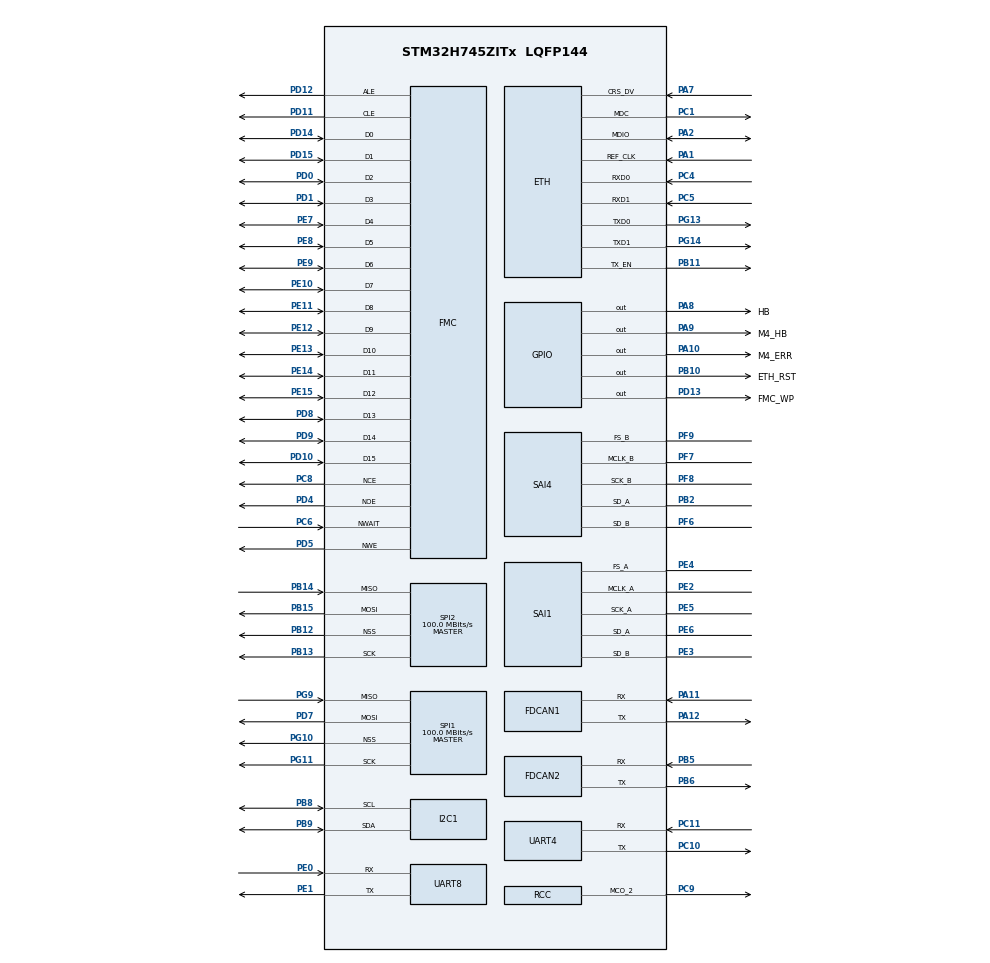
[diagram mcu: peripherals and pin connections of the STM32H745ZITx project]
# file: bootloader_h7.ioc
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CORTEX_M7.AccessPermission_S-Cortex_Memory_Protection_Unit_Region1_Settings_S=MPU_REGION_FULL_ACCESS
CORTEX_M7.AccessPermission_Spec=MPU_REGION_FULL_ACCESS
CORTEX_M7.BaseAddress_S-Cortex_Memory_Protection_Unit_Region1_Settings_S=0x30040000
CORTEX_M7.BaseAddress_Spec=0x30040000
CORTEX_M7.CPU_DCache=Enabled
CORTEX_M7.CPU_ICache=Enabled
CORTEX_M7.DisableExec_S-Cortex_Memory_Protection_Unit_Region1_Settings_S=MPU_INSTRUCTION_ACCESS_DISABLE
CORTEX_M7.Enable_S-Cortex_Memory_Protection_Unit_Region1_Settings_S=MPU_REGION_ENABLE
CORTEX_M7.IsBufferable_S-Cortex_Memory_Protection_Unit_Region1_Settings_S=MPU_ACCESS_BUFFERABLE
CORTEX_M7.IsShareable_S-Cortex_Memory_Protection_Unit_Region1_Settings_S=MPU_ACCESS_SHAREABLE
CORTEX_M7.IsShareable_Spec=MPU_ACCESS_NOT_SHAREABLE
CORTEX_M7.MPU_Control=__NULL
CORTEX_M7.Size_S-Cortex_Memory_Protection_Unit_Region1_Settings_S=MPU_REGION_SIZE_256B
CORTEX_M7.Size_Spec=MPU_REGION_SIZE_128KB
CORTEX_M7.SubRegionDisable_Spec=0x0
CORTEX_M7.TypeExtField_Spec=MPU_TEX_LEVEL1
CORTEX_M7.default_mode_Activation=1
CortexM4.IPs=CORTEX_M4\:I,DEBUG,FATFS_M4\:I,FREERTOS_M4\:I,IWDG2\:I,OPENAMP_M4\:I,PDM2PCM_M4\:I,PWR,RCC,RESMGR_UTILITY,SYS_M4\:I,USB_DEVICE_M4\:I,USB_HOST_M4\:I,VREFBUF,WWDG2\:I,DMA,BDMA,MDMA,NVIC2\:I,GPIO
CortexM4.Pins=PA9,PA10
CortexM7.IPs=CORTEX_M7\:I,DEBUG\:I,FATFS_M7\:I,FREERTOS_M7\:I,IWDG1\:I,OPENAMP_M7\:I,PDM2PCM_M7\:I,PWR\:I,RCC\:I,RESMGR_UTILITY\:I,SYS\:I,USB_DEVICE_M7\:I,USB_HOST_M7\:I,VREFBUF\:I,WWDG1\:I,DMA\:I,BDMA\:I,MDMA\:I,NVIC1\:I,ETH\:I,FDCAN1\:I,FDCAN2\:I,FMC\:I,UART4\:I,SPI1\:I,SPI2\:I,SAI1\:I,I2C1\:I,UART8\:I,SAI4\:I,GPIO\:I,TIM1\:I
CortexM7.Pins=PB10,PA8
ETH.MACAddr=00\:80\:E1\:00\:00\:01
ETH.MediaInterface=HAL_ETH_RMII_MODE
ETH.RxBuffLen=1536
ETH.RxDescAddress=0x30040000
ETH.TxDescAddress=0x30040200
FDCAN1.AutoRetransmission=ENABLE
FDCAN1.CalculateBaudRateNominal=1000000
FDCAN1.CalculateTimeBitNominal=1000
FDCAN1.CalculateTimeQuantumNominal=62.5
FDCAN1.NominalPrescaler=4
FDCAN1.NominalTimeSeg1=13
FDCAN1.RxFifo0ElmtsNbr=64
FDCAN1.StdFiltersNbr=28
FDCAN1.TxFifoQueueElmtsNbr=32
FDCAN2.AutoRetransmission=ENABLE
FDCAN2.CalculateBaudRateNominal=1000000
FDCAN2.CalculateTimeBitNominal=1000
FDCAN2.CalculateTimeQuantumNominal=62.5
FDCAN2.NominalPrescaler=4
FDCAN2.NominalTimeSeg1=13
FDCAN2.RxFifo0ElmtsNbr=64
FDCAN2.StdFiltersNbr=28
FDCAN2.TxFifoQueueElmtsNbr=32
FMC.NandBlockSize1=64
FMC.NandExtraCommandEnable1=DISABLE
FMC.NandPageSize1=1056
FMC.NandPlaneNbr1=2
FMC.NandPlaneSize1=1024
FMC.NandSpareAreaSize1=64
FMC.TARSetupTime1=1
FMC.TCLRSetupTime1=1
I2C1.Timing=0x10C0ECFF
Mcu.Family=STM32H7
Mcu.Name=STM32H745ZITx
Mcu.Package=LQFP144
NVIC1.FDCAN1_IT0_IRQn=true\:0\:0\:false\:false\:true\:true\:true\:true
NVIC1.FDCAN1_IT1_IRQn=true\:0\:0\:false\:false\:true\:true\:true\:true
NVIC1.FDCAN2_IT0_IRQn=true\:0\:0\:false\:false\:true\:true\:true\:true
NVIC1.FDCAN2_IT1_IRQn=true\:0\:0\:false\:false\:true\:true\:true\:true
NVIC1.PriorityGroup=NVIC_PRIORITYGROUP_4
NVIC2.PriorityGroup=NVIC_PRIORITYGROUP_4
PA1.GPIO_PuPd=GPIO_PULLUP
PA1.GPIO_Speed=GPIO_SPEED_FREQ_VERY_HIGH
PA1.Mode=RMII
PA1.PinAttribute=CortexM7
PA1.Signal=ETH_REF_CLK
PA10.GPIO_Label=M4_ERR
PA10.PinAttribute=CortexM4
PA10.Signal=GPIO_Output
PA11.Mode=FDCAN_Activate
PA11.PinAttribute=CortexM7
PA11.Signal=FDCAN1_RX
PA12.Mode=FDCAN_Activate
PA12.PinAttribute=CortexM7
PA12.Signal=FDCAN1_TX
PA13\ (JTMS/SWDIO).Mode=Trace_Asynchronous_SW
PA13\ (JTMS/SWDIO).PinAttribute=CortexM7
PA13\ (JTMS/SWDIO).Signal=DEBUG_JTMS-SWDIO
PA14\ (JTCK/SWCLK).Mode=Trace_Asynchronous_SW
PA14\ (JTCK/SWCLK).PinAttribute=CortexM7
PA14\ (JTCK/SWCLK).Signal=DEBUG_JTCK-SWCLK
PA2.GPIO_PuPd=GPIO_PULLUP
PA2.GPIO_Speed=GPIO_SPEED_FREQ_VERY_HIGH
PA2.Mode=RMII
PA2.PinAttribute=CortexM7
PA2.Signal=ETH_MDIO
PA7.GPIO_PuPd=GPIO_PULLUP
PA7.GPIO_Speed=GPIO_SPEED_FREQ_VERY_HIGH
PA7.Mode=RMII
PA7.PinAttribute=CortexM7
PA7.Signal=ETH_CRS_DV
PA8.GPIO_Label=HB
PA8.PinAttribute=CortexM7
PA8.Signal=GPIO_Output
PA9.GPIO_Label=M4_HB
PA9.PinAttribute=CortexM4
PA9.Signal=GPIO_Output
PB1.Signal=ADCx_INP5
PB10.GPIO_Label=ETH_RST
PB10.GPIO_PuPd=GPIO_PULLDOWN
PB10.GPIO_Speed=GPIO_SPEED_FREQ_MEDIUM
PB10.PinAttribute=CortexM7
PB10.Signal=GPIO_Output
PB11.GPIO_Speed=GPIO_SPEED_FREQ_VERY_HIGH
PB11.Mode=RMII
PB11.PinAttribute=CortexM7
PB11.Signal=ETH_TX_EN
PB12.Mode=NSS_Signal_Hard_Output
PB12.PinAttribute=CortexM7
PB12.Signal=SPI2_NSS
PB13.Mode=Full_Duplex_Master
PB13.PinAttribute=CortexM7
PB13.Signal=SPI2_SCK
PB14.Mode=Full_Duplex_Master
PB14.PinAttribute=CortexM7
PB14.Signal=SPI2_MISO
PB15.Mode=Full_Duplex_Master
PB15.PinAttribute=CortexM7
PB15.Signal=SPI2_MOSI
PB2.Mode=SAI_A_SyncSlave
PB2.PinAttribute=CortexM7
PB2.Signal=SAI4_SD_A
PB3\ (JTDO/TRACESWO).Mode=Trace_Asynchronous_SW
PB3\ (JTDO/TRACESWO).PinAttribute=CortexM7
PB3\ (JTDO/TRACESWO).Signal=DEBUG_JTDO-SWO
PB5.Mode=FDCAN_Activate
PB5.PinAttribute=CortexM7
PB5.Signal=FDCAN2_RX
PB6.Mode=FDCAN_Activate
PB6.PinAttribute=CortexM7
PB6.Signal=FDCAN2_TX
PB8.Mode=I2C
PB8.PinAttribute=CortexM7
PB8.Signal=I2C1_SCL
PB9.Mode=I2C
PB9.PinAttribute=CortexM7
PB9.Signal=I2C1_SDA
PC1.GPIO_Speed=GPIO_SPEED_FREQ_VERY_HIGH
PC1.Mode=RMII
PC1.PinAttribute=CortexM7
PC1.Signal=ETH_MDC
PC10.Mode=Asynchronous
PC10.PinAttribute=CortexM7
PC10.Signal=UART4_TX
PC11.Mode=Asynchronous
PC11.PinAttribute=CortexM7
PC11.Signal=UART4_RX
PC14-OSC32_IN\ (OSC32_IN).Mode=LSE-External-Oscillator
PC14-OSC32_IN\ (OSC32_IN).PinAttribute=CortexM7
PC14-OSC32_IN\ (OSC32_IN).Signal=RCC_OSC32_IN
PC15-OSC32_OUT\ (OSC32_OUT).Mode=LSE-External-Oscillator
PC15-OSC32_OUT\ (OSC32_OUT).PinAttribute=CortexM7
PC15-OSC32_OUT\ (OSC32_OUT).Signal=RCC_OSC32_OUT
PC4.GPIO_PuPd=GPIO_PULLUP
PC4.GPIO_Speed=GPIO_SPEED_FREQ_VERY_HIGH
PC4.Mode=RMII
PC4.PinAttribute=CortexM7
PC4.Signal=ETH_RXD0
PC5.GPIO_PuPd=GPIO_PULLUP
PC5.GPIO_Speed=GPIO_SPEED_FREQ_VERY_HIGH
PC5.Mode=RMII
PC5.PinAttribute=CortexM7
PC5.Signal=ETH_RXD1
PC6.PinAttribute=CortexM7
PC6.Signal=FMC_NWAIT
PC8.Mode=NandChipSelect3_1
PC8.PinAttribute=CortexM7
PC8.Signal=FMC_NCE
PC9.Mode=Clock-out-2
PC9.PinAttribute=Free
PC9.Signal=RCC_MCO_2
PD0.PinAttribute=CortexM7
PD0.Signal=FMC_D2_DA2
PD1.PinAttribute=CortexM7
PD1.Signal=FMC_D3_DA3
PD10.PinAttribute=CortexM7
PD10.Signal=FMC_D15_DA15
PD11.PinAttribute=CortexM7
PD11.Signal=FMC_A16_CLE
PD12.PinAttribute=CortexM7
PD12.Signal=FMC_A17_ALE
PD13.GPIO_Label=FMC_WP
PD13.PinAttribute=Free
PD13.Signal=GPIO_Output
PD14.PinAttribute=CortexM7
PD14.Signal=FMC_D0_DA0
PD15.PinAttribute=CortexM7
PD15.Signal=FMC_D1_DA1
PD4.PinAttribute=CortexM7
PD4.Signal=FMC_NOE
PD5.PinAttribute=CortexM7
PD5.Signal=FMC_NWE
PD7.Mode=Full_Duplex_Master
PD7.PinAttribute=CortexM7
PD7.Signal=SPI1_MOSI
PD8.PinAttribute=CortexM7
PD8.Signal=FMC_D13_DA13
PD9.PinAttribute=CortexM7
PD9.Signal=FMC_D14_DA14
PE0.Mode=Asynchronous
PE0.PinAttribute=CortexM7
PE0.Signal=UART8_RX
PE1.Mode=Asynchronous
PE1.PinAttribute=CortexM7
PE1.Signal=UART8_TX
PE10.PinAttribute=CortexM7
PE10.Signal=FMC_D7_DA7
PE11.PinAttribute=CortexM7
PE11.Signal=FMC_D8_DA8
PE12.PinAttribute=CortexM7
PE12.Signal=FMC_D9_DA9
PE13.PinAttribute=CortexM7
PE13.Signal=FMC_D10_DA10
PE14.PinAttribute=CortexM7
PE14.Signal=FMC_D11_DA11
PE15.PinAttribute=CortexM7
PE15.Signal=FMC_D12_DA12
PE2.Mode=SAI_A_MasterWithClock
PE2.PinAttribute=CortexM7
PE2.Signal=SAI1_MCLK_A
PE3.Mode=SAI_B_SyncSlave
PE3.PinAttribute=CortexM7
PE3.Signal=SAI1_SD_B
PE4.Mode=SAI_A_MasterWithClock
PE4.PinAttribute=CortexM7
PE4.Signal=SAI1_FS_A
PE5.Mode=SAI_A_MasterWithClock
PE5.PinAttribute=CortexM7
PE5.Signal=SAI1_SCK_A
PE6.Mode=SAI_A_MasterWithClock
PE6.PinAttribute=CortexM7
PE6.Signal=SAI1_SD_A
PE7.PinAttribute=CortexM7
PE7.Signal=FMC_D4_DA4
PE8.PinAttribute=CortexM7
PE8.Signal=FMC_D5_DA5
PE9.PinAttribute=CortexM7
PE9.Signal=FMC_D6_DA6
PF6.Mode=SAI_B_MasterWithClock
PF6.PinAttribute=CortexM7
PF6.Signal=SAI4_SD_B
PF7.Mode=SAI_B_MasterWithClock
PF7.PinAttribute=CortexM7
PF7.Signal=SAI4_MCLK_B
PF8.Mode=SAI_B_MasterWithClock
PF8.PinAttribute=CortexM7
PF8.Signal=SAI4_SCK_B
PF9.Mode=SAI_B_MasterWithClock
PF9.PinAttribute=CortexM7
PF9.Signal=SAI4_FS_B
PG10.Mode=NSS_Signal_Hard_Output
PG10.PinAttribute=CortexM7
PG10.Signal=SPI1_NSS
PG11.Mode=Full_Duplex_Master
PG11.PinAttribute=CortexM7
PG11.Signal=SPI1_SCK
PG13.GPIO_Speed=GPIO_SPEED_FREQ_VERY_HIGH
PG13.Mode=RMII
PG13.PinAttribute=CortexM7
PG13.Signal=ETH_TXD0
PG14.GPIO_Speed=GPIO_SPEED_FREQ_VERY_HIGH
PG14.Mode=RMII
PG14.PinAttribute=CortexM7
PG14.Signal=ETH_TXD1
PG7.PinAttribute=CortexM7
PG7.Signal=FMC_INT
PG9.Mode=Full_Duplex_Master
PG9.PinAttribute=CortexM7
PG9.Signal=SPI1_MISO
PH0-OSC_IN\ (PH0).Mode=HSE-External-Oscillator
PH0-OSC_IN\ (PH0).PinAttribute=CortexM7
PH0-OSC_IN\ (PH0).Signal=RCC_OSC_IN
PH1-OSC_OUT\ (PH1).Mode=HSE-External-Oscillator
PH1-OSC_OUT\ (PH1).PinAttribute=CortexM7
PH1-OSC_OUT\ (PH1).Signal=RCC_OSC_OUT
ProjectManager.HeapSize=M4-0x200,M7-0x200
ProjectManager.StackSize=M4-0x400,M7-0x400
ProjectManager.TargetToolchain=STM32CubeIDE
RCC.ADCFreq_Value=64000000
RCC.APB1Freq_Value=100000000
RCC.APB2Freq_Value=100000000
RCC.APB3Freq_Value=100000000
RCC.APB4Freq_Value=100000000
RCC.CortexFreq_Value=400000000
RCC.DIVM1=1
RCC.DIVM2=4
RCC.DIVN1=100
RCC.DIVN2=128
RCC.DIVP2=4
RCC.DIVQ1=4
RCC.DIVQ2=4
RCC.FDCANCLockSelection=RCC_FDCANCLKSOURCE_PLL2
RCC.HCLKFreq_Value=100000000
RCC.HPRE=RCC_HCLK_DIV4
RCC.HSE_VALUE=8000000
RCC.PLL2FRACN=0
RCC.PLL3FRACN=0
RCC.PLLFRACN=0
RCC.PLLSourceVirtual=RCC_PLLSOURCE_HSE
RCC.PWR_Regulator_Voltage_Scale=PWR_REGULATOR_VOLTAGE_SCALE1
RCC.RCC_MCO2Source=RCC_MCO2SOURCE_PLL2PCLK
RCC.RCC_MCODiv2=RCC_MCODIV_2
RCC.SAI1CLockSelection=RCC_SAI1CLKSOURCE_PLL2
RCC.SAI4ACLockSelection=RCC_SAI4ACLKSOURCE_PLL2
RCC.SAI4BCLockSelection=RCC_SAI4BCLKSOURCE_PLL2
RCC.SYSCLKFreq_VALUE=400000000
RCC.SYSCLKSource=RCC_SYSCLKSOURCE_PLLCLK
RCC.SupplySource=PWR_SMPS_1V8_SUPPLIES_EXT_AND_LDO
RCC.USBFreq_Value=200000000
SAI1.ErrorAudioFreq-SAI_A_MasterWithClock=30.2 %
SAI1.Instance-SAI_A_MasterWithClock=SAI$Index_Block_A
SAI1.Instance-SAI_B_SyncSlave=SAI$Index_Block_B
SAI1.MClockEnable-SAI_A_MasterWithClock=SAI_MASTERCLOCK_ENABLE
SAI1.RealAudioFreq-SAI_A_MasterWithClock=250.0 KHz
SAI1.VirtualMode-SAI_A_MasterWithClock=VM_MASTER
SAI1.VirtualMode-SAI_B_SyncSlave=VM_SLAVE
SAI4.ErrorAudioFreq-SAI_B_MasterWithClock=30.2 %
SAI4.Instance-SAI_A_SyncSlave=SAI$Index_Block_A
SAI4.Instance-SAI_B_MasterWithClock=SAI$Index_Block_B
SAI4.MClockEnable-SAI_B_MasterWithClock=SAI_MASTERCLOCK_ENABLE
SAI4.RealAudioFreq-SAI_B_MasterWithClock=250.0 KHz
SAI4.VirtualMode-SAI_A_SyncSlave=VM_SLAVE
SAI4.VirtualMode-SAI_B_MasterWithClock=VM_MASTER
SH.ADCx_INP5.0=ADC1_INP5
SH.FMC_A16_CLE.0=FMC_CLE,16b-dmux1
SH.FMC_A17_ALE.0=FMC_ALE,16b-dmux1
SH.FMC_D0_DA0.0=FMC_D0,16b-dmux1
SH.FMC_D10_DA10.0=FMC_D10,16b-dmux1
SH.FMC_D11_DA11.0=FMC_D11,16b-dmux1
SH.FMC_D12_DA12.0=FMC_D12,16b-dmux1
SH.FMC_D13_DA13.0=FMC_D13,16b-dmux1
SH.FMC_D14_DA14.0=FMC_D14,16b-dmux1
SH.FMC_D15_DA15.0=FMC_D15,16b-dmux1
SH.FMC_D1_DA1.0=FMC_D1,16b-dmux1
SH.FMC_D2_DA2.0=FMC_D2,16b-dmux1
SH.FMC_D3_DA3.0=FMC_D3,16b-dmux1
SH.FMC_D4_DA4.0=FMC_D4,16b-dmux1
SH.FMC_D5_DA5.0=FMC_D5,16b-dmux1
SH.FMC_D6_DA6.0=FMC_D6,16b-dmux1
SH.FMC_D7_DA7.0=FMC_D7,16b-dmux1
SH.FMC_D8_DA8.0=FMC_D8,16b-dmux1
SH.FMC_D9_DA9.0=FMC_D9,16b-dmux1
SH.FMC_INT.0=FMC_INT
SH.FMC_NOE.0=FMC_NOE,16b-dmux1
SH.FMC_NWAIT.0=FMC_NWAIT,Wait1
SH.FMC_NWE.0=FMC_NWE,16b-dmux1
SPI1.CalculateBaudRate=100.0 MBits/s
SPI1.Direction=SPI_DIRECTION_2LINES
SPI1.Mode=SPI_MODE_MASTER
SPI1.VirtualNSS=VM_NSSHARD
SPI1.VirtualType=VM_MASTER
SPI2.CalculateBaudRate=100.0 MBits/s
SPI2.Direction=SPI_DIRECTION_2LINES
SPI2.Mode=SPI_MODE_MASTER
SPI2.VirtualNSS=VM_NSSHARD
SPI2.VirtualType=VM_MASTER
SYS.userName=SYS_M7
VP_SYS_M4_VS_Systick.Mode=SysTick
VP_TIM1_VS_ClockSourceINT.Mode=Internal
board=custom

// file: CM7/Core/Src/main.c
/* USER CODE BEGIN Header */
/**
 ******************************************************************************
 * @file           : main.c
 * @brief          : Main program body
 ******************************************************************************
 * @attention
 *
 * Copyright (c) 2023 STMicroelectronics.
 * All rights reserved.
 *
 * This software is licensed under terms that can be found in the LICENSE file
 * in the root directory of this software component.
 * If no LICENSE file comes with this software, it is provided AS-IS.
 *
 ******************************************************************************
 */
/* USER CODE END Header */
#include "main.h"
#include "eth.h"
#include "fdcan.h"
#include "i2c.h"
#include "sai.h"
#include "spi.h"
#include "tim.h"
#include "usart.h"
#include "gpio.h"
#include "fmc.h"

/* USER CODE BEGIN Includes */
#include "canopen_bootloader.h"
#include <stdio.h>

/* USER CODE END Includes */

/* USER CODE BEGIN PD */

#ifndef HSEM_ID_0
#define HSEM_ID_0 (0U) /* HW semaphore 0*/
#endif

/* USER CODE END PD */

/* USER CODE BEGIN PM */
int _write(int _, const unsigned char *ptr, int len) {
  HAL_UART_Transmit(&huart4, ptr, len, HAL_MAX_DELAY);
  return len;
}
/* USER CODE END PM */

void SystemClock_Config(void);
void PeriphCommonClock_Config(void);

int main(void)
{
/* USER CODE BEGIN Boot_Mode_Sequence_0 */
  int32_t timeout;
/* USER CODE END Boot_Mode_Sequence_0 */
/* Enable the CPU Cache */

  /* Enable I-Cache---------------------------------------------------------*/
  SCB_EnableICache();

  /* Enable D-Cache---------------------------------------------------------*/
  SCB_EnableDCache();

/* USER CODE BEGIN Boot_Mode_Sequence_1 */
  /* Wait until CPU2 boots and enters in stop mode or timeout*/
  /*
  timeout = 0xFFFF;
  while((__HAL_RCC_GET_FLAG(RCC_FLAG_D2CKRDY) != RESET) && (timeout-- > 0));
  if ( timeout < 0 )
  {
  Error_Handler();
  }
   */
/* USER CODE END Boot_Mode_Sequence_1 */
  /* MCU Configuration--------------------------------------------------------*/

  /* Reset of all peripherals, Initializes the Flash interface and the Systick. */
  HAL_Init();

  /* Configure the system clock */
  SystemClock_Config();

/* Configure the peripherals common clocks */
  PeriphCommonClock_Config();
/* USER CODE BEGIN Boot_Mode_Sequence_2 */
  /* When system initialization is finished, Cortex-M7 will release Cortex-M4 by
  means of HSEM notification */
  /*HW semaphore Clock enable*/
  __HAL_RCC_HSEM_CLK_ENABLE();
  /*Take HSEM */
  HAL_HSEM_FastTake(HSEM_ID_0);
  /*Release HSEM in order to notify the CPU2(CM4)*/
  HAL_HSEM_Release(HSEM_ID_0, 0);
  /* wait until CPU2 wakes up from stop mode */
  /*
  timeout = 0xFFFF;
  while((__HAL_RCC_GET_FLAG(RCC_FLAG_D2CKRDY) == RESET) && (timeout-- > 0));
  if ( timeout < 0 )
  {
  Error_Handler();
  }
   */
/* USER CODE END Boot_Mode_Sequence_2 */

  /* Initialize all configured peripherals */
  MX_GPIO_Init();
  MX_FDCAN1_Init();
  MX_FDCAN2_Init();
  MX_FMC_Init();
  MX_SPI1_Init();
  MX_SPI2_Init();
  MX_UART4_Init();
  MX_SAI1_Init();
  MX_I2C1_Init();
  MX_UART8_Init();
  MX_SAI4_Init();
  MX_TIM1_Init();
  MX_ETH_Init();
  /* USER CODE BEGIN 2 */
  canopen_bootloader_run();
  /* USER CODE END 2 */

  /* Infinite loop */
  while (1) {

    /* USER CODE BEGIN 3 */
    main_loop();
  }
  /* USER CODE END 3 */
}

void SystemClock_Config(void)
{
  RCC_OscInitTypeDef RCC_OscInitStruct = {0};
  RCC_ClkInitTypeDef RCC_ClkInitStruct = {0};

  /** Supply configuration update enable
  */
  HAL_PWREx_ConfigSupply(PWR_SMPS_1V8_SUPPLIES_EXT_AND_LDO);

  /** Configure the main internal regulator output voltage
  */
  __HAL_PWR_VOLTAGESCALING_CONFIG(PWR_REGULATOR_VOLTAGE_SCALE1);

  while(!__HAL_PWR_GET_FLAG(PWR_FLAG_VOSRDY)) {}

  /** Initializes the RCC Oscillators according to the specified parameters
  * in the RCC_OscInitTypeDef structure.
  */
  RCC_OscInitStruct.OscillatorType = RCC_OSCILLATORTYPE_HSE;
  RCC_OscInitStruct.HSEState = RCC_HSE_ON;
  RCC_OscInitStruct.PLL.PLLState = RCC_PLL_ON;
  RCC_OscInitStruct.PLL.PLLSource = RCC_PLLSOURCE_HSE;
  RCC_OscInitStruct.PLL.PLLM = 1;
  RCC_OscInitStruct.PLL.PLLN = 100;
  RCC_OscInitStruct.PLL.PLLP = 2;
  RCC_OscInitStruct.PLL.PLLQ = 4;
  RCC_OscInitStruct.PLL.PLLR = 2;
  RCC_OscInitStruct.PLL.PLLRGE = RCC_PLL1VCIRANGE_3;
  RCC_OscInitStruct.PLL.PLLVCOSEL = RCC_PLL1VCOWIDE;
  RCC_OscInitStruct.PLL.PLLFRACN = 0;
  if (HAL_RCC_OscConfig(&RCC_OscInitStruct) != HAL_OK)
  {
    Error_Handler();
  }

  /** Initializes the CPU, AHB and APB buses clocks
  */
  RCC_ClkInitStruct.ClockType = RCC_CLOCKTYPE_HCLK|RCC_CLOCKTYPE_SYSCLK
                              |RCC_CLOCKTYPE_PCLK1|RCC_CLOCKTYPE_PCLK2
                              |RCC_CLOCKTYPE_D3PCLK1|RCC_CLOCKTYPE_D1PCLK1;
  RCC_ClkInitStruct.SYSCLKSource = RCC_SYSCLKSOURCE_PLLCLK;
  RCC_ClkInitStruct.SYSCLKDivider = RCC_SYSCLK_DIV1;
  RCC_ClkInitStruct.AHBCLKDivider = RCC_HCLK_DIV4;
  RCC_ClkInitStruct.APB3CLKDivider = RCC_APB3_DIV1;
  RCC_ClkInitStruct.APB1CLKDivider = RCC_APB1_DIV1;
  RCC_ClkInitStruct.APB2CLKDivider = RCC_APB2_DIV1;
  RCC_ClkInitStruct.APB4CLKDivider = RCC_APB4_DIV1;

  if (HAL_RCC_ClockConfig(&RCC_ClkInitStruct, FLASH_LATENCY_1) != HAL_OK)
  {
    Error_Handler();
  }
  HAL_RCC_MCOConfig(RCC_MCO2, RCC_MCO2SOURCE_PLL2PCLK, RCC_MCODIV_2);
}

void PeriphCommonClock_Config(void)
{
  RCC_PeriphCLKInitTypeDef PeriphClkInitStruct = {0};

  /** Initializes the peripherals clock
  */
  PeriphClkInitStruct.PeriphClockSelection = RCC_PERIPHCLK_SAI4A|RCC_PERIPHCLK_SAI4B
                              |RCC_PERIPHCLK_SAI1|RCC_PERIPHCLK_FDCAN;
  PeriphClkInitStruct.PLL2.PLL2M = 4;
  PeriphClkInitStruct.PLL2.PLL2N = 128;
  PeriphClkInitStruct.PLL2.PLL2P = 4;
  PeriphClkInitStruct.PLL2.PLL2Q = 4;
  PeriphClkInitStruct.PLL2.PLL2R = 2;
  PeriphClkInitStruct.PLL2.PLL2RGE = RCC_PLL2VCIRANGE_1;
  PeriphClkInitStruct.PLL2.PLL2VCOSEL = RCC_PLL2VCOWIDE;
  PeriphClkInitStruct.PLL2.PLL2FRACN = 0;
  PeriphClkInitStruct.Sai1ClockSelection = RCC_SAI1CLKSOURCE_PLL2;
  PeriphClkInitStruct.FdcanClockSelection = RCC_FDCANCLKSOURCE_PLL2;
  PeriphClkInitStruct.Sai4AClockSelection = RCC_SAI4ACLKSOURCE_PLL2;
  PeriphClkInitStruct.Sai4BClockSelection = RCC_SAI4BCLKSOURCE_PLL2;
  if (HAL_RCCEx_PeriphCLKConfig(&PeriphClkInitStruct) != HAL_OK)
  {
    Error_Handler();
  }
}

void Error_Handler(void)
{
  __disable_irq();
  while (1) {
  }
}

#ifdef  USE_FULL_ASSERT
/**
  * @brief  Reports the name of the source file and the source line number
  *         where the assert_param error has occurred.
  * @param  file: pointer to the source file name
  * @param  line: assert_param error line source number
  * @retval None
  */
void assert_failed(uint8_t *file, uint32_t line)
{
  /* USER CODE BEGIN 6 */
  /* User can add his own implementation to report the file name and line
     number, ex: printf("Wrong parameters value: file %s on line %d\r\n", file,
     line) */
  /* USER CODE END 6 */
}
#endif /* USE_FULL_ASSERT */
